VERSION ""

NS_ :

BS_:

BU_: DBG DRIVER MOTOR BRIDGE_SENSOR GEO

BO_ 100 DRIVER_HEARTBEAT: 1 DRIVER
 SG_ DRIVER_HEARTBEAT_CMD : 0|8@1+ (1,0) [0|0] "" BRIDGE_SENSOR,MOTOR,GEO

BO_ 101 MOTOR_HEARTBEAT: 1 MOTOR
 SG_ MOTOR_HEARTBEAT_CMD : 0|8@1+ (1,0) [0|0] "" DRIVER

BO_ 102 DRIVER_MOTOR_CONTROL: 8 DRIVER
 SG_ DRIVER_MOTOR_CONTROL_SPEED_KPH : 0|32@1- (0.001,0) [-10|10] "kph" MOTOR
 SG_ DRIVER_MOTOR_CONTROL_STEER : 32|32@1- (0.001,0) [0.0|4.0] "degrees" MOTOR

BO_ 103 MOTOR_ACTUAL_SPEED: 4 MOTOR
 SG_ MOTOR_ACTUAL_SPEED_KPH : 0|32@1- (0.001,0) [-10|10] "kph" DRIVER,BRIDGE_SENSOR

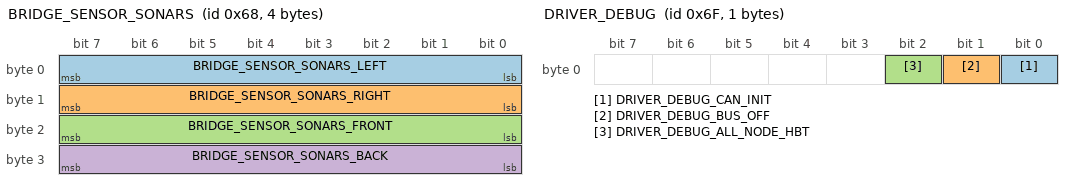
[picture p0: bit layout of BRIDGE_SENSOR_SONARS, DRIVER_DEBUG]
BO_ 104 BRIDGE_SENSOR_SONARS: 4 BRIDGE_SENSOR
 SG_ BRIDGE_SENSOR_SONARS_LEFT : 0|8@1+ (1,0) [0|99] "inch" DRIVER
 SG_ BRIDGE_SENSOR_SONARS_RIGHT : 8|8@1+ (1,0) [0|99] "inch" DRIVER
 SG_ BRIDGE_SENSOR_SONARS_FRONT : 16|8@1+ (1,0) [0|99] "inch" DRIVER
 SG_ BRIDGE_SENSOR_SONARS_BACK : 24|8@1+ (1,0) [0|99] "inch" DRIVER

BO_ 105 GEO_GPS_COMPASS_HEADINGS: 8 GEO
 SG_ GEO_GPS_COMPASS_HEADINGS_CURRENT : 0|32@1- (0.000001,0) [0|360] "degrees" DRIVER, BRIDGE_SENSOR
 SG_ GEO_GPS_COMPASS_HEADINGS_DESTINATION : 32|32@1- (0.000001,0) [0|360] "degrees" DRIVER, BRIDGE_SENSOR

BO_ 117 GEO_GPS_DISTANCE: 4 GEO
 SG_ GEO_GPS_DISTANCE_TO_DESTINATION : 0|32@1- (0.000001,0) [0|0] "meters" DRIVER, BRIDGE_SENSOR

BO_ 113 GEO_GPS_COMPASS_DBG: 8 GEO
 SG_ GEO_GPS_BETA : 0|32@1- (0.000001,0) [0|360] "degrees" DBG
 SG_ GEO_GPS_NEXT_POINT_INDEX : 32|8@1+ (1,0) [0|0] "" DBG, DRIVER

BO_ 114 GEO_GPS_COMPASS_DBG_2: 8 GEO
 SG_ GEO_GPS_HEADINGS_LATITUDE_INT : 0|32@1- (0.000001,0) [0|2000] "degrees" DBG
 SG_ GEO_GPS_HEADINGS_LONGITUDE_INT : 32|32@1- (0.000001,0) [0|2000] "degrees" DBG

BO_ 115 GEO_GPS_COMPASS_DBG_3: 8 GEO
 SG_ GEO_GPS_CURRENT_LATITUDE_INT : 0|32@1- (0.000001,0) [0|2000] "degrees" DBG
 SG_ GEO_GPS_CURRENT_LONGITUDE_INT : 32|32@1- (0.000001,0) [0|2000] "degrees" DBG

BO_ 116 GEO_GPS_COMPASS_DBG_4: 8 GEO
 SG_ GEO_GPS_RECEIVED_LATITUDE : 0|32@1- (0.000001,0) [0|2000] "degrees" DBG, DRIVER
 SG_ GEO_GPS_RECEIVED_LONGITUDE : 32|32@1- (0.000001,0) [0|2000] "degrees" DBG, DRIVER

BO_ 106 BRIDGE_SENSOR_GPS_HEADINGS: 8 BRIDGE_SENSOR
 SG_ BRIDGE_SENSOR_GPS_HEADINGS_LONGITUDE : 0|32@1- (0.000001, 0) [0|2000] "degrees" GEO, DRIVER
 SG_ BRIDGE_SENSOR_GPS_HEADINGS_LATITUDE : 32|32@1- (0.000001, 0) [0|2000] "degrees" GEO, DRIVER

BO_ 107 BRIDGE_SENSOR_VOLTAGE: 4 BRIDGE_SENSOR
 SG_ BRIDGE_SENSOR_VOLTAGE : 0|32@1+ (0.000001, 0) [0|0] "volts" DRIVER

BO_ 108 BRIDGE_SENSOR_VEHICLE_NAVIGATION_STATE: 1 BRIDGE_SENSOR
 SG_ BRIDGE_SENSOR_VEHICLE_NAVIGATION_STATE : 0|8@1+ (1,0) [0|0] "" DRIVER, MOTOR, GEO

BO_ 109 BRIDGE_SENSOR_HEARTBEAT: 1 BRIDGE_SENSOR
 SG_ BRIDGE_SENSOR_HEARTBEAT_CMD : 0|8@1+ (1,0) [0|0] "" DRIVER

BO_ 110 GEO_HEARTBEAT: 1 GEO
 SG_ GEO_HEARTBEAT_CMD : 0|8@1+ (1,0) [0|0] "" DRIVER

BO_ 111 DRIVER_DEBUG: 1 DRIVER
 SG_ DRIVER_DEBUG_CAN_INIT : 0|1@1+ (1,0) [0|0] "" DBG
 SG_ DRIVER_DEBUG_BUS_OFF : 1|1@1+ (1,0) [0|0] "" DBG
 SG_ DRIVER_DEBUG_ALL_NODE_HBT : 2|1@1+ (1,0) [0|0] "" DBG

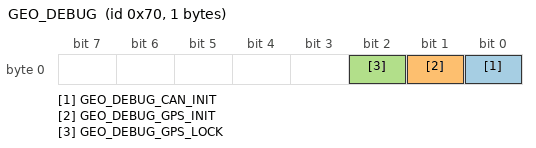
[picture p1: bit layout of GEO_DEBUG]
BO_ 112 GEO_DEBUG: 1 GEO
 SG_ GEO_DEBUG_CAN_INIT : 0|1@1+ (1,0) [0|0] "" DBG
 SG_ GEO_DEBUG_GPS_INIT : 1|1@1+ (1,0) [0|0] "" DBG
 SG_ GEO_DEBUG_GPS_LOCK : 2|1@1+ (1,0) [0|0] "" DBG

CM_ BU_ DBG "The driver controller driving the car";
CM_ BU_ DRIVER "The driver controller driving the car";
CM_ BU_ MOTOR "The motor controller of the car";
CM_ BU_ BRIDGE_SENSOR "The bridge and sensor controller of the car";
CM_ BU_ GEO "The geological controller of the car";
CM_ BO_ 100 "Sync message used to synchronize the controllers";
CM_ SG_ 100 DRIVER_HEARTBEAT_CMD "Heartbeat command from the driver";
CM_ SG_ 101 MOTOR_HEARTBEAT_CMD "Heartbeat command from the motor";
CM_ SG_ 108 BRIDGE_SENSOR_VEHICLE_NAVIGATION_STATE "Navigation commands from the bridge_sensor controller";

BA_DEF_ "BusType" STRING ;
BA_DEF_ BO_ "GenMsgCycleTime" INT 0 0;
BA_DEF_ SG_ "FieldType" STRING ;
BA_DEF_DEF_ "BusType" "CAN";
BA_DEF_DEF_ "FieldType" "";
BA_DEF_DEF_ "GenMsgCycleTime" 0;

BA_ "GenMsgCycleTime" BO_ 100 1000;
BA_ "GenMsgCycleTime" BO_ 101 1000;
BA_ "GenMsgCycleTime" BO_ 102 100;
BA_ "GenMsgCycleTime" BO_ 103 50;
BA_ "GenMsgCycleTime" BO_ 104 50;
BA_ "GenMsgCycleTime" BO_ 105 100;
BA_ "GenMsgCycleTime" BO_ 106 100;
BA_ "GenMsgCycleTime" BO_ 107 100;
BA_ "GenMsgCycleTime" BO_ 108 100;
BA_ "GenMsgCycleTime" BO_ 109 100;
BA_ "GenMsgCycleTime" BO_ 110 100;

BA_ "FieldType" SG_ 100 DRIVER_HEARTBEAT_CMD "DRIVER_HEARTBEAT_CMD";
BA_ "FieldType" SG_ 101 MOTOR_HEARTBEAT_CMD "MOTOR_HEARTBEAT_CMD";
BA_ "FieldType" SG_ 108 BRIDGE_SENSOR_VEHICLE_NAVIGATION_STATE "BRIDGE_SENSOR_VEHICLE_NAVIGATION_STATE";
BA_ "FieldType" SG_ 109 BRIDGE_SENSOR_HEARTBEAT_CMD "BRIDGE_SENSOR_HEARTBEAT_CMD";
BA_ "FieldType" SG_ 110 GEO_HEARTBEAT_CMD "GEO_HEARTBEAT_CMD";

VAL_ 100 DRIVER_HEARTBEAT_CMD 2 "DRIVER_HEARTBEAT_CMD_REBOOT" 1 "DRIVER_HEARTBEAT_CMD_SYNC" 0 "DRIVER_HEARTBEAT_CMD_NOOP" ;
VAL_ 101 MOTOR_HEARTBEAT_CMD 2 "MOTOR_HEARTBEAT_CMD_REBOOT" 1 "MOTOR_HEARTBEAT_CMD_SYNC" 0 "MOTOR_HEARTBEAT_CMD_NOOP" ;
VAL_ 108 BRIDGE_SENSOR_VEHICLE_NAVIGATION_STATE 1 "BRIDGE_SENSOR_VEHICLE_NAVIGATION_STATE_STOP" 0 "BRIDGE_SENSOR_VEHICLE_NAVIGATION_STATE_NAVIGATE" ;
VAL_ 109 BRIDGE_SENSOR_HEARTBEAT_CMD 2 "BRIDGE_SENSOR_HEARTBEAT_CMD_REBOOT" 1 "BRIDGE_SENSOR_HEARTBEAT_CMD_SYNC" 0 "BRIDGE_SENSOR_HEARTBEAT_CMD_NOOP" ;
VAL_ 110 GEO_HEARTBEAT_CMD 2 "GEO_HEARTBEAT_CMD_REBOOT" 1 "GEO_HEARTBEAT_CMD_SYNC" 0 "GEO_HEARTBEAT_CMD_NOOP" ;
